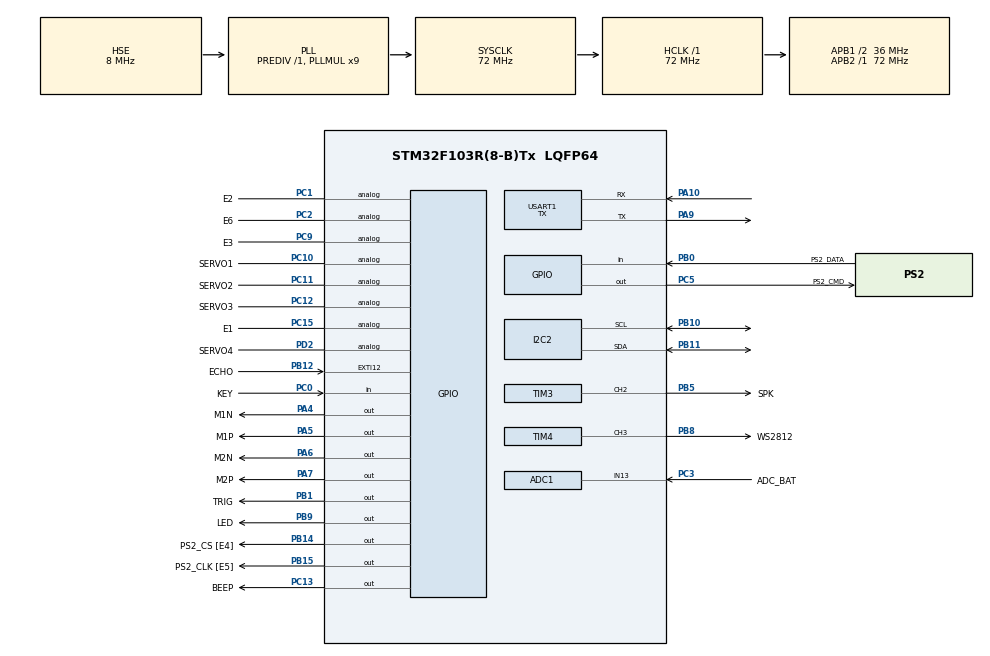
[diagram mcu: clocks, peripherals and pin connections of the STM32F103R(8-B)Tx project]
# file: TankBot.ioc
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ADC1.Channel-0\#ChannelRegularConversion=ADC_CHANNEL_13
ADC1.NbrOfConversionFlag=1
ADC1.Rank-0\#ChannelRegularConversion=1
ADC1.SamplingTime-0\#ChannelRegularConversion=ADC_SAMPLETIME_239CYCLES_5
ADC1.master=1
Dma.Request0=TIM2_UP
Dma.Request1=TIM4_CH3
Dma.Request2=TIM3_CH4/UP
Dma.TIM2_UP.0.Direction=DMA_PERIPH_TO_MEMORY
Dma.TIM2_UP.0.Instance=DMA1_Channel2
Dma.TIM2_UP.0.MemDataAlignment=DMA_MDATAALIGN_WORD
Dma.TIM2_UP.0.MemInc=DMA_MINC_DISABLE
Dma.TIM2_UP.0.Mode=DMA_CIRCULAR
Dma.TIM2_UP.0.PeriphDataAlignment=DMA_PDATAALIGN_WORD
Dma.TIM2_UP.0.PeriphInc=DMA_PINC_DISABLE
Dma.TIM2_UP.0.Priority=DMA_PRIORITY_LOW
Dma.TIM3_CH4/UP.2.Direction=DMA_MEMORY_TO_PERIPH
Dma.TIM3_CH4/UP.2.Instance=DMA1_Channel3
Dma.TIM3_CH4/UP.2.MemDataAlignment=DMA_MDATAALIGN_WORD
Dma.TIM3_CH4/UP.2.MemInc=DMA_MINC_ENABLE
Dma.TIM3_CH4/UP.2.Mode=DMA_CIRCULAR
Dma.TIM3_CH4/UP.2.PeriphDataAlignment=DMA_PDATAALIGN_WORD
Dma.TIM3_CH4/UP.2.PeriphInc=DMA_PINC_DISABLE
Dma.TIM3_CH4/UP.2.Priority=DMA_PRIORITY_LOW
Dma.TIM4_CH3.1.Direction=DMA_MEMORY_TO_PERIPH
Dma.TIM4_CH3.1.Instance=DMA1_Channel5
Dma.TIM4_CH3.1.MemDataAlignment=DMA_MDATAALIGN_WORD
Dma.TIM4_CH3.1.MemInc=DMA_MINC_ENABLE
Dma.TIM4_CH3.1.Mode=DMA_CIRCULAR
Dma.TIM4_CH3.1.PeriphDataAlignment=DMA_PDATAALIGN_WORD
Dma.TIM4_CH3.1.PeriphInc=DMA_PINC_DISABLE
Dma.TIM4_CH3.1.Priority=DMA_PRIORITY_LOW
FREERTOS.MEMORY_ALLOCATION=0
FREERTOS.Mutexes01=ps2_mutex,Dynamic,NULL;servo_mutex,Dynamic,NULL;beep_mutex,Dynamic,NULL;i2c_mutex,Dynamic,NULL;display_mutex,Dynamic,NULL
FREERTOS.Tasks01=defaultTask,0,512,app_main,As weak,NULL,Dynamic,NULL,NULL;servo_task,0,128,servo_daemon,As external,NULL,Dynamic,NULL,NULL;beep_task,-2,128,beep_daemon,As external,NULL,Dynamic,NULL,NULL
FREERTOS.Timers01=ps2_timer,ps2_raw_read,osTimerPeriodic,As external,NULL,Dynamic,NULL;ultrasonic_timer,ultrasonic_task,osTimerPeriodic,As external,NULL,Dynamic,NULL;display_timer,display_task,osTimerPeriodic,As external,NULL,Dynamic,NULL
FREERTOS.configENABLE_BACKWARD_COMPATIBILITY=0
FREERTOS.configMAX_CO_ROUTINE_PRIORITIES=2
FREERTOS.configTIMER_TASK_PRIORITY=5
FREERTOS.configTOTAL_HEAP_SIZE=6144
FREERTOS.configUSE_TASK_NOTIFICATIONS=1
FREERTOS.configUSE_TIMERS=1
I2C2.I2C_Mode=I2C_Fast
Mcu.Family=STM32F1
Mcu.Name=STM32F103R(8-B)Tx
Mcu.Package=LQFP64
NVIC.DMA1_Channel2_IRQn=true\:5\:0\:false\:false\:true\:true\:false
NVIC.DMA1_Channel3_IRQn=true\:5\:0\:false\:false\:true\:true\:false
NVIC.DMA1_Channel5_IRQn=true\:5\:0\:false\:false\:true\:true\:false
NVIC.EXTI15_10_IRQn=true\:5\:0\:false\:false\:true\:true\:true
NVIC.PriorityGroup=NVIC_PRIORITYGROUP_4
NVIC.TIM2_IRQn=true\:5\:0\:false\:false\:true\:true\:true
PA10.Mode=Asynchronous
PA10.Signal=USART1_RX
PA4.GPIO_Label=M1N
PA4.GPIO_Speed=GPIO_SPEED_FREQ_HIGH
PA4.Signal=GPIO_Output
PA5.GPIO_Label=M1P
PA5.GPIO_Speed=GPIO_SPEED_FREQ_HIGH
PA5.Signal=GPIO_Output
PA6.GPIO_Label=M2N
PA6.GPIO_Speed=GPIO_SPEED_FREQ_HIGH
PA6.Signal=GPIO_Output
PA7.GPIO_Label=M2P
PA7.GPIO_Speed=GPIO_SPEED_FREQ_HIGH
PA7.Signal=GPIO_Output
PA9.Mode=Asynchronous
PA9.Signal=USART1_TX
PB0.GPIO_Label=PS2_DATA
PB0.GPIO_PuPd=GPIO_PULLDOWN
PB0.Signal=GPIO_Input
PB1.GPIO_Label=TRIG
PB1.Signal=GPIO_Output
PB10.Mode=I2C
PB10.Signal=I2C2_SCL
PB11.Mode=I2C
PB11.Signal=I2C2_SDA
PB12.GPIO_Label=ECHO
PB12.GPIO_ModeDefaultEXTI=GPIO_MODE_IT_RISING_FALLING
PB12.Signal=GPXTI12
PB14.GPIO_Label=PS2_CS [E4]
PB14.PinState=GPIO_PIN_SET
PB14.Signal=GPIO_Output
PB15.GPIO_Label=PS2_CLK [E5]
PB15.GPIO_Speed=GPIO_SPEED_FREQ_HIGH
PB15.PinState=GPIO_PIN_SET
PB15.Signal=GPIO_Output
PB5.GPIO_Label=SPK
PB5.GPIO_ModeDefaultPP=GPIO_MODE_AF_PP
PB5.GPIO_Speed=GPIO_SPEED_FREQ_HIGH
PB5.Signal=S_TIM3_CH2
PB8.GPIO_Label=WS2812
PB8.GPIO_Speed=GPIO_SPEED_FREQ_HIGH
PB8.Signal=S_TIM4_CH3
PB9.GPIO_Label=LED
PB9.PinState=GPIO_PIN_SET
PB9.Signal=GPIO_Output
PC0.GPIO_Label=KEY
PC0.GPIO_PuPd=GPIO_PULLUP
PC0.Signal=GPIO_Input
PC1.GPIO_Label=E2
PC1.Signal=GPIO_Analog
PC10.GPIO_Label=SERVO1
PC10.Signal=GPIO_Analog
PC11.GPIO_Label=SERVO2
PC11.Signal=GPIO_Analog
PC12.GPIO_Label=SERVO3
PC12.Signal=GPIO_Analog
PC13-TAMPER-RTC.GPIO_Label=BEEP
PC13-TAMPER-RTC.Signal=GPIO_Output
PC15-OSC32_OUT.GPIO_Label=E1
PC15-OSC32_OUT.Signal=GPIO_Analog
PC2.GPIO_Label=E6
PC2.Signal=GPIO_Analog
PC3.GPIO_Label=ADC_BAT
PC3.Signal=ADCx_IN13
PC5.GPIO_Label=PS2_CMD
PC5.GPIO_Speed=GPIO_SPEED_FREQ_HIGH
PC5.Signal=GPIO_Output
PC9.GPIO_Label=E3
PC9.Signal=GPIO_Analog
PD0-OSC_IN.Mode=HSE-External-Oscillator
PD0-OSC_IN.Signal=RCC_OSC_IN
PD1-OSC_OUT.Mode=HSE-External-Oscillator
PD1-OSC_OUT.Signal=RCC_OSC_OUT
PD2.GPIO_Label=SERVO4
PD2.Signal=GPIO_Analog
ProjectManager.HeapSize=0x200
ProjectManager.StackSize=0x400
ProjectManager.TargetToolchain=MDK-ARM V5
RCC.ADCPresc=RCC_ADCPCLK2_DIV6
RCC.AHBFreq_Value=72000000
RCC.APB1CLKDivider=RCC_HCLK_DIV2
RCC.APB1Freq_Value=36000000
RCC.APB1TimFreq_Value=72000000
RCC.APB2Freq_Value=72000000
RCC.APB2TimFreq_Value=72000000
RCC.HCLKFreq_Value=72000000
RCC.PLLMUL=RCC_PLL_MUL9
RCC.PLLSourceVirtual=RCC_PLLSOURCE_HSE
RCC.SYSCLKFreq_VALUE=72000000
RCC.SYSCLKSource=RCC_SYSCLKSOURCE_PLLCLK
RCC.USBFreq_Value=72000000
SH.ADCx_IN13.0=ADC1_IN13,IN13
SH.S_TIM3_CH2.0=TIM3_CH2,PWM Generation2 CH2
SH.S_TIM4_CH3.0=TIM4_CH3,PWM Generation3 CH3
TIM2.Channel-Output\ Compare1\ No\ Output=TIM_CHANNEL_1
TIM2.Channel-Output\ Compare2\ No\ Output=TIM_CHANNEL_2
TIM2.Period=10000-1
TIM2.Prescaler=72-1
TIM3.AutoReloadPreload=TIM_AUTORELOAD_PRELOAD_DISABLE
TIM3.Channel-PWM\ Generation2\ CH2=TIM_CHANNEL_2
TIM3.OCFastMode_PWM-PWM\ Generation2\ CH2=TIM_OCFAST_DISABLE
TIM3.Period=2273-1
TIM3.Prescaler=72-1
TIM3.Pulse-PWM\ Generation2\ CH2=0
TIM4.Channel-PWM\ Generation3\ CH3=TIM_CHANNEL_3
TIM4.Period=90-1
USART1.Mode=MODE_TX
USART1.VirtualMode=VM_ASYNC
VP_FREERTOS_VS_ENABLE.Mode=Enabled
VP_SYS_VS_ND.Mode=No_Debug
VP_TIM2_VS_no_output1.Mode=Output Compare1 No Output
VP_TIM2_VS_no_output2.Mode=Output Compare2 No Output
board=custom

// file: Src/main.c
/* USER CODE BEGIN Header */
/**
  ******************************************************************************
  * @file           : main.c
  * @brief          : Main program body
  ******************************************************************************
  ** This notice applies to any and all portions of this file
  * that are not between comment pairs USER CODE BEGIN and
  * USER CODE END. Other portions of this file, whether
  * inserted by the user or by software development tools
  * are owned by their respective copyright owners.
  *
  * COPYRIGHT(c) 2019 STMicroelectronics
  *
  * Redistribution and use in source and binary forms, with or without modification,
  * are permitted provided that the following conditions are met:
  *   1. Redistributions of source code must retain the above copyright notice,
  *      this list of conditions and the following disclaimer.
  *   2. Redistributions in binary form must reproduce the above copyright notice,
  *      this list of conditions and the following disclaimer in the documentation
  *      and/or other materials provided with the distribution.
  *   3. Neither the name of STMicroelectronics nor the names of its contributors
  *      may be used to endorse or promote products derived from this software
  *      without specific prior written permission.
  *
  * THIS SOFTWARE IS PROVIDED BY THE COPYRIGHT HOLDERS AND CONTRIBUTORS "AS IS"
  * AND ANY EXPRESS OR IMPLIED WARRANTIES, INCLUDING, BUT NOT LIMITED TO, THE
  * IMPLIED WARRANTIES OF MERCHANTABILITY AND FITNESS FOR A PARTICULAR PURPOSE ARE
  * DISCLAIMED. IN NO EVENT SHALL THE COPYRIGHT HOLDER OR CONTRIBUTORS BE LIABLE
  * FOR ANY DIRECT, INDIRECT, INCIDENTAL, SPECIAL, EXEMPLARY, OR CONSEQUENTIAL
  * DAMAGES (INCLUDING, BUT NOT LIMITED TO, PROCUREMENT OF SUBSTITUTE GOODS OR
  * SERVICES; LOSS OF USE, DATA, OR PROFITS; OR BUSINESS INTERRUPTION) HOWEVER
  * CAUSED AND ON ANY THEORY OF LIABILITY, WHETHER IN CONTRACT, STRICT LIABILITY,
  * OR TORT (INCLUDING NEGLIGENCE OR OTHERWISE) ARISING IN ANY WAY OUT OF THE USE
  * OF THIS SOFTWARE, EVEN IF ADVISED OF THE POSSIBILITY OF SUCH DAMAGE.
  *
  ******************************************************************************
  */
/* USER CODE END Header */

#include "main.h"
#include "cmsis_os.h"

ADC_HandleTypeDef hadc1;

I2C_HandleTypeDef hi2c2;

TIM_HandleTypeDef htim2;
TIM_HandleTypeDef htim3;
TIM_HandleTypeDef htim4;
DMA_HandleTypeDef hdma_tim2_up;
DMA_HandleTypeDef hdma_tim3_ch4_up;
DMA_HandleTypeDef hdma_tim4_ch3;

UART_HandleTypeDef huart1;

osThreadId defaultTaskHandle;
osThreadId servo_taskHandle;
osThreadId beep_taskHandle;
osTimerId ps2_timerHandle;
osTimerId ultrasonic_timerHandle;
osTimerId display_timerHandle;
osMutexId ps2_mutexHandle;
osMutexId servo_mutexHandle;
osMutexId beep_mutexHandle;
osMutexId i2c_mutexHandle;
osMutexId display_mutexHandle;
/* USER CODE BEGIN PV */
#ifdef __GNUC__
  /* With GCC/RAISONANCE, small printf (option LD Linker->Libraries->Small printf
     set to 'Yes') calls __io_putchar() */
  #define PUTCHAR_PROTOTYPE int __io_putchar(int ch)
#else
  #define PUTCHAR_PROTOTYPE int fputc(int ch, FILE *f)
#endif /* __GNUC__ */
/**
  * @brief  Retargets the C library printf function to the USART.
  * @param  None
  * @retval None
  */
PUTCHAR_PROTOTYPE
{
#if !defined(NDEBUG) && defined(HAL_UART_MODULE_ENABLED)
  /* Place your implementation of fputc here */
  /* e.g. write a character to the EVAL_COM1 and Loop until the end of transmission */
  HAL_UART_Transmit(&huart1, (uint8_t *)&ch, 1, 0xFFFF);
#endif

  return ch;
}
/* USER CODE END PV */

void SystemClock_Config(void);
static void MX_GPIO_Init(void);
static void MX_DMA_Init(void);
static void MX_USART1_UART_Init(void);
static void MX_TIM3_Init(void);
static void MX_ADC1_Init(void);
static void MX_TIM2_Init(void);
static void MX_TIM4_Init(void);
static void MX_I2C2_Init(void);
void app_main(void const * argument);
extern void servo_daemon(void const * argument);
extern void beep_daemon(void const * argument);
extern void ps2_raw_read(void const * argument);
extern void ultrasonic_task(void const * argument);
extern void display_task(void const * argument);

int main(void)
{

  /* MCU Configuration--------------------------------------------------------*/

  /* Reset of all peripherals, Initializes the Flash interface and the Systick. */
  HAL_Init();

  /* Configure the system clock */
  SystemClock_Config();

  /* Initialize all configured peripherals */
  MX_GPIO_Init();
  MX_DMA_Init();
  MX_USART1_UART_Init();
  MX_TIM3_Init();
  MX_ADC1_Init();
  MX_TIM2_Init();
  MX_TIM4_Init();
  MX_I2C2_Init();

  /* Create the mutex(es) */
  /* definition and creation of ps2_mutex */
  osMutexDef(ps2_mutex);
  ps2_mutexHandle = osMutexCreate(osMutex(ps2_mutex));

  /* definition and creation of servo_mutex */
  osMutexDef(servo_mutex);
  servo_mutexHandle = osMutexCreate(osMutex(servo_mutex));

  /* definition and creation of beep_mutex */
  osMutexDef(beep_mutex);
  beep_mutexHandle = osMutexCreate(osMutex(beep_mutex));

  /* definition and creation of i2c_mutex */
  osMutexDef(i2c_mutex);
  i2c_mutexHandle = osMutexCreate(osMutex(i2c_mutex));

  /* definition and creation of display_mutex */
  osMutexDef(display_mutex);
  display_mutexHandle = osMutexCreate(osMutex(display_mutex));

  /* Create the timer(s) */
  /* definition and creation of ps2_timer */
  osTimerDef(ps2_timer, ps2_raw_read);
  ps2_timerHandle = osTimerCreate(osTimer(ps2_timer), osTimerPeriodic, NULL);

  /* definition and creation of ultrasonic_timer */
  osTimerDef(ultrasonic_timer, ultrasonic_task);
  ultrasonic_timerHandle = osTimerCreate(osTimer(ultrasonic_timer), osTimerPeriodic, NULL);

  /* definition and creation of display_timer */
  osTimerDef(display_timer, display_task);
  display_timerHandle = osTimerCreate(osTimer(display_timer), osTimerPeriodic, NULL);

  /* Create the thread(s) */
  /* definition and creation of defaultTask */
  osThreadDef(defaultTask, app_main, osPriorityNormal, 0, 512);
  defaultTaskHandle = osThreadCreate(osThread(defaultTask), NULL);

  /* definition and creation of servo_task */
  osThreadDef(servo_task, servo_daemon, osPriorityNormal, 0, 128);
  servo_taskHandle = osThreadCreate(osThread(servo_task), NULL);

  /* definition and creation of beep_task */
  osThreadDef(beep_task, beep_daemon, osPriorityLow, 0, 128);
  beep_taskHandle = osThreadCreate(osThread(beep_task), NULL);

  /* Start scheduler */
  osKernelStart();

  /* We should never get here as control is now taken by the scheduler */

  /* Infinite loop */
  while (1)
  {

  }
}

void SystemClock_Config(void)
{
  RCC_OscInitTypeDef RCC_OscInitStruct = {0};
  RCC_ClkInitTypeDef RCC_ClkInitStruct = {0};
  RCC_PeriphCLKInitTypeDef PeriphClkInit = {0};

  /**Initializes the CPU, AHB and APB busses clocks
  */
  RCC_OscInitStruct.OscillatorType = RCC_OSCILLATORTYPE_HSE;
  RCC_OscInitStruct.HSEState = RCC_HSE_ON;
  RCC_OscInitStruct.HSEPredivValue = RCC_HSE_PREDIV_DIV1;
  RCC_OscInitStruct.HSIState = RCC_HSI_ON;
  RCC_OscInitStruct.PLL.PLLState = RCC_PLL_ON;
  RCC_OscInitStruct.PLL.PLLSource = RCC_PLLSOURCE_HSE;
  RCC_OscInitStruct.PLL.PLLMUL = RCC_PLL_MUL9;
  if (HAL_RCC_OscConfig(&RCC_OscInitStruct) != HAL_OK)
  {
    Error_Handler();
  }
  /**Initializes the CPU, AHB and APB busses clocks
  */
  RCC_ClkInitStruct.ClockType = RCC_CLOCKTYPE_HCLK|RCC_CLOCKTYPE_SYSCLK
                              |RCC_CLOCKTYPE_PCLK1|RCC_CLOCKTYPE_PCLK2;
  RCC_ClkInitStruct.SYSCLKSource = RCC_SYSCLKSOURCE_PLLCLK;
  RCC_ClkInitStruct.AHBCLKDivider = RCC_SYSCLK_DIV1;
  RCC_ClkInitStruct.APB1CLKDivider = RCC_HCLK_DIV2;
  RCC_ClkInitStruct.APB2CLKDivider = RCC_HCLK_DIV1;

  if (HAL_RCC_ClockConfig(&RCC_ClkInitStruct, FLASH_LATENCY_2) != HAL_OK)
  {
    Error_Handler();
  }
  PeriphClkInit.PeriphClockSelection = RCC_PERIPHCLK_ADC;
  PeriphClkInit.AdcClockSelection = RCC_ADCPCLK2_DIV6;
  if (HAL_RCCEx_PeriphCLKConfig(&PeriphClkInit) != HAL_OK)
  {
    Error_Handler();
  }
}

static void MX_ADC1_Init(void)
{

  ADC_ChannelConfTypeDef sConfig = {0};

  /**Common config
  */
  hadc1.Instance = ADC1;
  hadc1.Init.ScanConvMode = ADC_SCAN_DISABLE;
  hadc1.Init.ContinuousConvMode = DISABLE;
  hadc1.Init.DiscontinuousConvMode = DISABLE;
  hadc1.Init.ExternalTrigConv = ADC_SOFTWARE_START;
  hadc1.Init.DataAlign = ADC_DATAALIGN_RIGHT;
  hadc1.Init.NbrOfConversion = 1;
  if (HAL_ADC_Init(&hadc1) != HAL_OK)
  {
    Error_Handler();
  }
  /**Configure Regular Channel
  */
  sConfig.Channel = ADC_CHANNEL_13;
  sConfig.Rank = ADC_REGULAR_RANK_1;
  sConfig.SamplingTime = ADC_SAMPLETIME_239CYCLES_5;
  if (HAL_ADC_ConfigChannel(&hadc1, &sConfig) != HAL_OK)
  {
    Error_Handler();
  }

}

static void MX_I2C2_Init(void)
{

  hi2c2.Instance = I2C2;
  hi2c2.Init.ClockSpeed = 400000;
  hi2c2.Init.DutyCycle = I2C_DUTYCYCLE_2;
  hi2c2.Init.OwnAddress1 = 0;
  hi2c2.Init.AddressingMode = I2C_ADDRESSINGMODE_7BIT;
  hi2c2.Init.DualAddressMode = I2C_DUALADDRESS_DISABLE;
  hi2c2.Init.OwnAddress2 = 0;
  hi2c2.Init.GeneralCallMode = I2C_GENERALCALL_DISABLE;
  hi2c2.Init.NoStretchMode = I2C_NOSTRETCH_DISABLE;
  if (HAL_I2C_Init(&hi2c2) != HAL_OK)
  {
    Error_Handler();
  }

}

static void MX_TIM2_Init(void)
{

  TIM_MasterConfigTypeDef sMasterConfig = {0};
  TIM_OC_InitTypeDef sConfigOC = {0};

  htim2.Instance = TIM2;
  htim2.Init.Prescaler = 72-1;
  htim2.Init.CounterMode = TIM_COUNTERMODE_UP;
  htim2.Init.Period = 10000-1;
  htim2.Init.ClockDivision = TIM_CLOCKDIVISION_DIV1;
  htim2.Init.AutoReloadPreload = TIM_AUTORELOAD_PRELOAD_DISABLE;
  if (HAL_TIM_OC_Init(&htim2) != HAL_OK)
  {
    Error_Handler();
  }
  sMasterConfig.MasterOutputTrigger = TIM_TRGO_RESET;
  sMasterConfig.MasterSlaveMode = TIM_MASTERSLAVEMODE_DISABLE;
  if (HAL_TIMEx_MasterConfigSynchronization(&htim2, &sMasterConfig) != HAL_OK)
  {
    Error_Handler();
  }
  sConfigOC.OCMode = TIM_OCMODE_TIMING;
  sConfigOC.Pulse = 0;
  sConfigOC.OCPolarity = TIM_OCPOLARITY_HIGH;
  sConfigOC.OCFastMode = TIM_OCFAST_DISABLE;
  if (HAL_TIM_OC_ConfigChannel(&htim2, &sConfigOC, TIM_CHANNEL_1) != HAL_OK)
  {
    Error_Handler();
  }
  if (HAL_TIM_OC_ConfigChannel(&htim2, &sConfigOC, TIM_CHANNEL_2) != HAL_OK)
  {
    Error_Handler();
  }

}

static void MX_TIM3_Init(void)
{

  TIM_MasterConfigTypeDef sMasterConfig = {0};
  TIM_OC_InitTypeDef sConfigOC = {0};

  htim3.Instance = TIM3;
  htim3.Init.Prescaler = 72-1;
  htim3.Init.CounterMode = TIM_COUNTERMODE_UP;
  htim3.Init.Period = 2273-1;
  htim3.Init.ClockDivision = TIM_CLOCKDIVISION_DIV1;
  htim3.Init.AutoReloadPreload = TIM_AUTORELOAD_PRELOAD_DISABLE;
  if (HAL_TIM_PWM_Init(&htim3) != HAL_OK)
  {
    Error_Handler();
  }
  sMasterConfig.MasterOutputTrigger = TIM_TRGO_RESET;
  sMasterConfig.MasterSlaveMode = TIM_MASTERSLAVEMODE_DISABLE;
  if (HAL_TIMEx_MasterConfigSynchronization(&htim3, &sMasterConfig) != HAL_OK)
  {
    Error_Handler();
  }
  sConfigOC.OCMode = TIM_OCMODE_PWM1;
  sConfigOC.Pulse = 0;
  sConfigOC.OCPolarity = TIM_OCPOLARITY_HIGH;
  sConfigOC.OCFastMode = TIM_OCFAST_DISABLE;
  if (HAL_TIM_PWM_ConfigChannel(&htim3, &sConfigOC, TIM_CHANNEL_2) != HAL_OK)
  {
    Error_Handler();
  }
  HAL_TIM_MspPostInit(&htim3);

}

static void MX_TIM4_Init(void)
{

  TIM_MasterConfigTypeDef sMasterConfig = {0};
  TIM_OC_InitTypeDef sConfigOC = {0};

  htim4.Instance = TIM4;
  htim4.Init.Prescaler = 0;
  htim4.Init.CounterMode = TIM_COUNTERMODE_UP;
  htim4.Init.Period = 90-1;
  htim4.Init.ClockDivision = TIM_CLOCKDIVISION_DIV1;
  htim4.Init.AutoReloadPreload = TIM_AUTORELOAD_PRELOAD_DISABLE;
  if (HAL_TIM_PWM_Init(&htim4) != HAL_OK)
  {
    Error_Handler();
  }
  sMasterConfig.MasterOutputTrigger = TIM_TRGO_RESET;
  sMasterConfig.MasterSlaveMode = TIM_MASTERSLAVEMODE_DISABLE;
  if (HAL_TIMEx_MasterConfigSynchronization(&htim4, &sMasterConfig) != HAL_OK)
  {
    Error_Handler();
  }
  sConfigOC.OCMode = TIM_OCMODE_PWM1;
  sConfigOC.Pulse = 0;
  sConfigOC.OCPolarity = TIM_OCPOLARITY_HIGH;
  sConfigOC.OCFastMode = TIM_OCFAST_DISABLE;
  if (HAL_TIM_PWM_ConfigChannel(&htim4, &sConfigOC, TIM_CHANNEL_3) != HAL_OK)
  {
    Error_Handler();
  }
  HAL_TIM_MspPostInit(&htim4);

}

static void MX_USART1_UART_Init(void)
{

  huart1.Instance = USART1;
  huart1.Init.BaudRate = 115200;
  huart1.Init.WordLength = UART_WORDLENGTH_8B;
  huart1.Init.StopBits = UART_STOPBITS_1;
  huart1.Init.Parity = UART_PARITY_NONE;
  huart1.Init.Mode = UART_MODE_TX;
  huart1.Init.HwFlowCtl = UART_HWCONTROL_NONE;
  huart1.Init.OverSampling = UART_OVERSAMPLING_16;
  if (HAL_UART_Init(&huart1) != HAL_OK)
  {
    Error_Handler();
  }

}

static void MX_DMA_Init(void)
{
  /* DMA controller clock enable */
  __HAL_RCC_DMA1_CLK_ENABLE();

  /* DMA interrupt init */
  /* DMA1_Channel2_IRQn interrupt configuration */
  HAL_NVIC_SetPriority(DMA1_Channel2_IRQn, 5, 0);
  HAL_NVIC_EnableIRQ(DMA1_Channel2_IRQn);
  /* DMA1_Channel3_IRQn interrupt configuration */
  HAL_NVIC_SetPriority(DMA1_Channel3_IRQn, 5, 0);
  HAL_NVIC_EnableIRQ(DMA1_Channel3_IRQn);
  /* DMA1_Channel5_IRQn interrupt configuration */
  HAL_NVIC_SetPriority(DMA1_Channel5_IRQn, 5, 0);
  HAL_NVIC_EnableIRQ(DMA1_Channel5_IRQn);

}

static void MX_GPIO_Init(void)
{
  GPIO_InitTypeDef GPIO_InitStruct = {0};

  /* GPIO Ports Clock Enable */
  __HAL_RCC_GPIOC_CLK_ENABLE();
  __HAL_RCC_GPIOD_CLK_ENABLE();
  __HAL_RCC_GPIOA_CLK_ENABLE();
  __HAL_RCC_GPIOB_CLK_ENABLE();

  /*Configure GPIO pin Output Level */
  HAL_GPIO_WritePin(GPIOC, BEEP_Pin|PS2_CMD_Pin, GPIO_PIN_RESET);

  /*Configure GPIO pin Output Level */
  HAL_GPIO_WritePin(GPIOA, M1N_Pin|M1P_Pin|M2N_Pin|M2P_Pin, GPIO_PIN_RESET);

  /*Configure GPIO pin Output Level */
  HAL_GPIO_WritePin(TRIG_GPIO_Port, TRIG_Pin, GPIO_PIN_RESET);

  /*Configure GPIO pin Output Level */
  HAL_GPIO_WritePin(GPIOB, PS2_CS_Pin|PS2_CLK_Pin|LED_Pin, GPIO_PIN_SET);

  /*Configure GPIO pin : BEEP_Pin */
  GPIO_InitStruct.Pin = BEEP_Pin;
  GPIO_InitStruct.Mode = GPIO_MODE_OUTPUT_PP;
  GPIO_InitStruct.Pull = GPIO_NOPULL;
  GPIO_InitStruct.Speed = GPIO_SPEED_FREQ_LOW;
  HAL_GPIO_Init(BEEP_GPIO_Port, &GPIO_InitStruct);

  /*Configure GPIO pins : E1_Pin E2_Pin E6_Pin E3_Pin
                           SERVO1_Pin SERVO2_Pin SERVO3_Pin */
  GPIO_InitStruct.Pin = E1_Pin|E2_Pin|E6_Pin|E3_Pin
                          |SERVO1_Pin|SERVO2_Pin|SERVO3_Pin;
  GPIO_InitStruct.Mode = GPIO_MODE_ANALOG;
  HAL_GPIO_Init(GPIOC, &GPIO_InitStruct);

  /*Configure GPIO pin : KEY_Pin */
  GPIO_InitStruct.Pin = KEY_Pin;
  GPIO_InitStruct.Mode = GPIO_MODE_INPUT;
  GPIO_InitStruct.Pull = GPIO_PULLUP;
  HAL_GPIO_Init(KEY_GPIO_Port, &GPIO_InitStruct);

  /*Configure GPIO pins : M1N_Pin M1P_Pin M2N_Pin M2P_Pin */
  GPIO_InitStruct.Pin = M1N_Pin|M1P_Pin|M2N_Pin|M2P_Pin;
  GPIO_InitStruct.Mode = GPIO_MODE_OUTPUT_PP;
  GPIO_InitStruct.Pull = GPIO_NOPULL;
  GPIO_InitStruct.Speed = GPIO_SPEED_FREQ_HIGH;
  HAL_GPIO_Init(GPIOA, &GPIO_InitStruct);

  /*Configure GPIO pin : PS2_CMD_Pin */
  GPIO_InitStruct.Pin = PS2_CMD_Pin;
  GPIO_InitStruct.Mode = GPIO_MODE_OUTPUT_PP;
  GPIO_InitStruct.Pull = GPIO_NOPULL;
  GPIO_InitStruct.Speed = GPIO_SPEED_FREQ_HIGH;
  HAL_GPIO_Init(PS2_CMD_GPIO_Port, &GPIO_InitStruct);

  /*Configure GPIO pin : PS2_DATA_Pin */
  GPIO_InitStruct.Pin = PS2_DATA_Pin;
  GPIO_InitStruct.Mode = GPIO_MODE_INPUT;
  GPIO_InitStruct.Pull = GPIO_PULLDOWN;
  HAL_GPIO_Init(PS2_DATA_GPIO_Port, &GPIO_InitStruct);

  /*Configure GPIO pins : TRIG_Pin PS2_CS_Pin LED_Pin */
  GPIO_InitStruct.Pin = TRIG_Pin|PS2_CS_Pin|LED_Pin;
  GPIO_InitStruct.Mode = GPIO_MODE_OUTPUT_PP;
  GPIO_InitStruct.Pull = GPIO_NOPULL;
  GPIO_InitStruct.Speed = GPIO_SPEED_FREQ_LOW;
  HAL_GPIO_Init(GPIOB, &GPIO_InitStruct);

  /*Configure GPIO pin : ECHO_Pin */
  GPIO_InitStruct.Pin = ECHO_Pin;
  GPIO_InitStruct.Mode = GPIO_MODE_IT_RISING_FALLING;
  GPIO_InitStruct.Pull = GPIO_NOPULL;
  HAL_GPIO_Init(ECHO_GPIO_Port, &GPIO_InitStruct);

  /*Configure GPIO pin : PS2_CLK_Pin */
  GPIO_InitStruct.Pin = PS2_CLK_Pin;
  GPIO_InitStruct.Mode = GPIO_MODE_OUTPUT_PP;
  GPIO_InitStruct.Pull = GPIO_NOPULL;
  GPIO_InitStruct.Speed = GPIO_SPEED_FREQ_HIGH;
  HAL_GPIO_Init(PS2_CLK_GPIO_Port, &GPIO_InitStruct);

  /*Configure GPIO pin : SERVO4_Pin */
  GPIO_InitStruct.Pin = SERVO4_Pin;
  GPIO_InitStruct.Mode = GPIO_MODE_ANALOG;
  HAL_GPIO_Init(SERVO4_GPIO_Port, &GPIO_InitStruct);

  /* EXTI interrupt init*/
  HAL_NVIC_SetPriority(EXTI15_10_IRQn, 5, 0);
  HAL_NVIC_EnableIRQ(EXTI15_10_IRQn);

}

__weak void app_main(void const * argument)
{

  for(;;)
  {
    osDelay(1);
  }
}

void Error_Handler(void)
{
}

/************************ (C) COPYRIGHT STMicroelectronics *****END OF FILE****/
